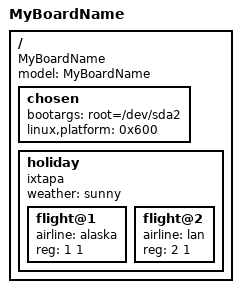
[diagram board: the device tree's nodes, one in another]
// SPDX-License-Identifier: GPL-2.0-or-later

/dts-v1/;
/memreserve/ 1 2;
/ {
	model = "MyBoardName";
	compatible = "MyBoardName", "MyBoardFamilyName";
	#address-cells = <1>;
	#size-cells = <1>;
	chosen {
		bootargs = "root=/dev/sda2";
		linux,platform = <0x600>;
	};
	holiday {
		compatible = "ixtapa", "mexico";
		weather = "sunny";
		status = "okay";
		#address-cells = <1>;
		#size-cells = <1>;
		flight@1 {
			airline = "alaska";
			reg = <1 1>;
		};
		flight@2 {
			airline = "lan";
			reg = <2 1>;
		};
	};
};
